# ESP32S31_RADIO register map
Vendor: Espressif; Series: ESP32-S31; File version: 3.52
Registers are 32-bit, read-write, no defined reset value unless marked. A register's access mark holds for its fields unless they carry their own. Offsets are from the block's base; [hi:lo] are bit positions; 'fields as' and 'values as' point back to an identical list.

## COEX_EXTERNAL_OBSERVED — Sparse source-qualified word views in the existing owned MMIO aperture; individual meanings and side effects remain unknown.
Base 0x2010F49C
0x18 WORD_0018_OPAQUE — Opaque: meaning not established. Aligned 32-bit bus view explicitly addressed by the cited vendor source. No reset or hardware write effect is established.
  [31:0] BITS_0_31_OPAQUE — Opaque: meaning not established. Observed source use; the individual hardware meaning is unknown.
0x1C WORD_001C_OPAQUE — Opaque: meaning not established. Aligned 32-bit bus view explicitly addressed by the cited vendor source. No reset or hardware write effect is established.
  fields as WORD_0018_OPAQUE

## WIFI_MAC_INTERNAL_TX_BLOCK_ACK — Complete dbg_read_internal_txba reads one internal WDEVTXBA result: a 64-bit bitmap, two transmitter-address words and a combined fragment/starting-sequence/TID word.
Base 0x2010429C
0x00 BITMAP_HIGH ro — Project-assigned name.
  [31:0] BITMAP — Project-assigned name. High 32 bits of the internal transmit BlockAck acknowledgement bitmap.
0x04 BITMAP_LOW ro — Project-assigned name.
  [31:0] BITMAP — Project-assigned name. Low 32 bits of the internal transmit BlockAck acknowledgement bitmap.
0x08 TRANSMITTER_ADDRESS_WORD_0 ro — Project-assigned name. First WDEVTXBA TA word printed by the complete blob decoder. Byte ordering is retained as a raw word until a matching live frame qualifies it.
  [31:0] BITS_0_31_OPAQUE — Opaque: meaning not established. Observed source use; the individual hardware meaning is unknown.
0x0C TRANSMITTER_ADDRESS_WORD_1 ro — Project-assigned name. Second WDEVTXBA TA word printed by the complete blob decoder. Byte ordering is retained as a raw word until a matching live frame qualifies it.
  fields as TRANSMITTER_ADDRESS_WORD_0
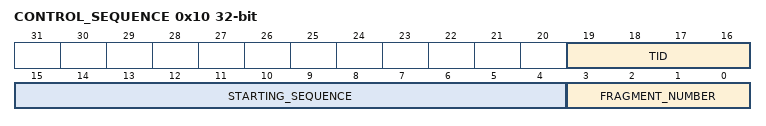
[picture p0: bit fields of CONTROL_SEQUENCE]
0x10 CONTROL_SEQUENCE ro — Project-assigned name.
  [19:16] TID — Project-assigned name.
  [15:4] STARTING_SEQUENCE — Project-assigned name.
  [3:0] FRAGMENT_NUMBER — Project-assigned name.

## WIFI_MAC_HE_COLOR_COLLISION — Complete dbg_read_color_collision reads the 64-bit observed BSS-color bitmap. Its adjacent control word is the canonical WIFI_MAC_HE_INIT_PREFIX.RX_FIELD_CONTROL register. Open HE HIL observed color bit 25, threshold one and timeout 60 seconds.
Base 0x20104040
0x00 BSS_COLOR_BITMAP_LOW ro — Project-assigned name. RX_HE_BSS_COLOR_MAPLO.
  [31:0] VALUE — Project-assigned name.
0x04 BSS_COLOR_BITMAP_HIGH ro — Project-assigned name. RX_HE_BSS_COLOR_MAPHI.
  [31:0] VALUE — Project-assigned name.

## WIFI_MAC_RX_POWER_SAVE — WDEV_RX_POWER_SAVE_CONF decoded by complete dbg_read_rx_misc. Complete hal_he_set_power_save sets the interface-zero intra-PPDU and BSS-color-check bits as the tail of hal_he_bssid_init; open associated-STA HIL read both bits set.
Base 0x201040A0
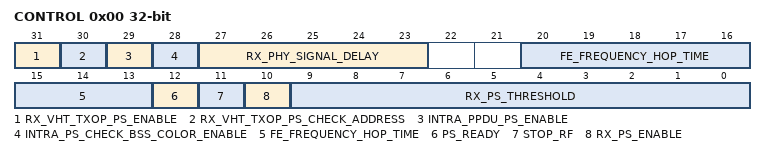
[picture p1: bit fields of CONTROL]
0x00 CONTROL — Project-assigned name.
  [31] RX_VHT_TXOP_PS_ENABLE — Project-assigned name.
  [30] RX_VHT_TXOP_PS_CHECK_ADDRESS — Project-assigned name.
  [29] INTRA_PPDU_PS_ENABLE — Project-assigned name. Complete hal_he_set_power_save sets bit 29 for interface zero immediately before bit 28; dbg_read_rx_misc names it INTRA_PPDU_PS.
  [28] INTRA_PS_CHECK_BSS_COLOR_ENABLE — Project-assigned name. Complete hal_he_set_power_save sets bit 28 for interface zero as the final fresh-read RMW of hal_he_bssid_init; dbg_read_rx_misc names it INTRA_PS_CHECK_BSS_COLOR.
  [27:23] RX_PHY_SIGNAL_DELAY — Project-assigned name.
  [20:13] FE_FREQUENCY_HOP_TIME — Project-assigned name.
  [12] PS_READY — Project-assigned name.
  [11] STOP_RF — Project-assigned name.
  [10] RX_PS_ENABLE — Project-assigned name.
  [9:0] RX_PS_THRESHOLD — Project-assigned name.
